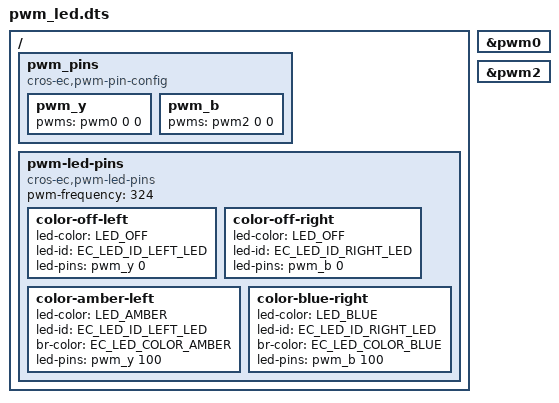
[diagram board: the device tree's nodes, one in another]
/* Copyright 2022 The Chromium OS Authors. All rights reserved.
 * Use of this source code is governed by a BSD-style license that can be
 * found in the LICENSE file.
 */

/ {
	pwm_pins {
		compatible = "cros-ec,pwm-pin-config";

		pwm_y: pwm_y {
			#led-pin-cells = <1>;
			pwms = <&pwm0 0 0>;
		};

		pwm_b: pwm_b {
			#led-pin-cells = <1>;
			pwms = <&pwm2 0 0>;
		};
	};

	pwm-led-pins {
		compatible = "cros-ec,pwm-led-pins";
		pwm-frequency = <324>;

		color-off-left {
			led-color = "LED_OFF";
			led-id = "EC_LED_ID_LEFT_LED";
			led-pins = <&pwm_y 0>;
		};

		color-off-right {
			led-color = "LED_OFF";
			led-id = "EC_LED_ID_RIGHT_LED";
			led-pins = <&pwm_b 0>;
		};

		color-amber-left {
			led-color = "LED_AMBER";
			led-id = "EC_LED_ID_LEFT_LED";
			br-color = "EC_LED_COLOR_AMBER";
			led-pins = <&pwm_y 100>;
		};

		color-blue-right {
			led-color = "LED_BLUE";
			led-id = "EC_LED_ID_RIGHT_LED";
			br-color = "EC_LED_COLOR_BLUE";
			led-pins = <&pwm_b 100>;
		};
	};
};

&pwm0 {
	status = "okay";
};

&pwm2 {
	status = "okay";
};
